AUTOSAR XML (schema 4-2-2)
package /ComponentTypes
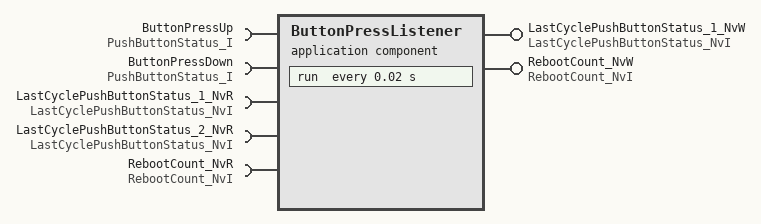
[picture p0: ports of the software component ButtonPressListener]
  application sw component type ButtonPressListener
    provide port LastCyclePushButtonStatus_1_NvW: nv-provide-com-spec{ram-block-init-value=constant-reference=LastCyclePushButtonStatus_IV, rom-block-init-value=constant-reference=LastCyclePushButtonStatus_IV, variable=LastCyclePushButtonStatus}, provided-interface=LastCyclePushButtonStatus_NvI
    provide port RebootCount_NvW: nv-provide-com-spec{ram-block-init-value=2, rom-block-init-value=3, variable=RebootCount}, provided-interface=RebootCount_NvI
    5 x require port:
      ButtonPressUp: queued-receiver-com-spec{data-element=PushButtonStatus, queue-length=10}, required-interface=PushButtonStatus_I
      ButtonPressDown: queued-receiver-com-spec{data-element=PushButtonStatus, queue-length=10}, required-interface=PushButtonStatus_I
      LastCyclePushButtonStatus_1_NvR: nv-require-com-spec{init-value=constant-reference=LastCyclePushButtonStatus_IV, variable=LastCyclePushButtonStatus}, required-interface=LastCyclePushButtonStatus_NvI
      LastCyclePushButtonStatus_2_NvR: nv-require-com-spec{init-value=LastCyclePushButtonStatus_IV:0, variable=LastCyclePushButtonStatus}, required-interface=LastCyclePushButtonStatus_NvI
      RebootCount_NvR: nv-require-com-spec{init-value=1, variable=RebootCount}, required-interface=RebootCount_NvI
    behavior ButtonPressListener_InternalBehavior
      timing event TMT_run: start-on-event=run, period=0.02
      port-api-options:
        enable-take-address=false, indirect-api=false, port=ButtonPressDown
        enable-take-address=false, indirect-api=false, port=ButtonPressUp
        enable-take-address=false, indirect-api=false, port=LastCyclePushButtonStatus_1_NvR
        enable-take-address=false, indirect-api=false, port=LastCyclePushButtonStatus_1_NvW
        enable-take-address=false, indirect-api=false, port=LastCyclePushButtonStatus_2_NvR
        enable-take-address=false, indirect-api=false, port=RebootCount_NvR
        enable-take-address=false, indirect-api=false, port=RebootCount_NvW
      runnable run
        data-receive-point-by-arguments:
          access REC_LastCyclePushButtonStatus_1_NvR_LastCyclePushButtonStatus: accessed-variable=LastCyclePushButtonStatus_1_NvR.LastCyclePushButtonStatus
        data-send-points:
          access SEND_LastCyclePushButtonStatus_1_NvW_LastCyclePushButtonStatus: accessed-variable=LastCyclePushButtonStatus_1_NvW.LastCyclePushButtonStatus
  swc implementation ButtonPressListener_Implementation: behavior=ButtonPressListener_InternalBehavior
    code-descriptors:
      code Default: artifact-descriptors=autosar-engineering-object={short-label=Default, category=SWSRC}
